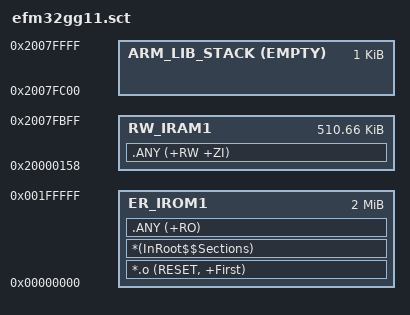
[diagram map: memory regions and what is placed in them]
#! armcc -E
; *************************************************************
; *** Scatter-Loading Description File generated by uVision ***
; *************************************************************

#if !defined(MBED_APP_START)
  #define MBED_APP_START 0x00000000
#endif

#if !defined(MBED_APP_SIZE)
  #define MBED_APP_SIZE 0x00200000
#endif

#if !defined(MBED_BOOT_STACK_SIZE)
  #define MBED_BOOT_STACK_SIZE 0x400
#endif

#define Stack_Size MBED_BOOT_STACK_SIZE

LR_IROM1 MBED_APP_START MBED_APP_SIZE  {    ; load region size_region
  ER_IROM1 MBED_APP_START MBED_APP_SIZE  {  ; load address = execution address
   *.o (RESET, +First)
   *(InRoot$$Sections)
   .ANY (+RO)
  }
  RW_IRAM1 0x20000158 0x0007FEA8-Stack_Size  {  ; RW data
   .ANY (+RW +ZI)
  }
  
  ARM_LIB_STACK (0x20000158+0x0007FEA8) EMPTY -Stack_Size { ; stack
  }
}

